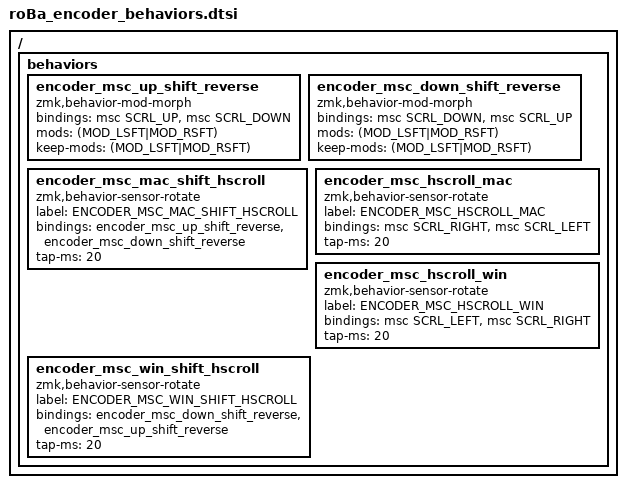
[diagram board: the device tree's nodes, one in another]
/ {
    behaviors {
        encoder_msc_up_shift_reverse: encoder_msc_up_shift_reverse {
            compatible = "zmk,behavior-mod-morph";
            #binding-cells = <0>;
            bindings = <&msc SCRL_UP>, <&msc SCRL_DOWN>;

            mods = <(MOD_LSFT|MOD_RSFT)>;
            keep-mods = <(MOD_LSFT|MOD_RSFT)>;
        };

        encoder_msc_down_shift_reverse: encoder_msc_down_shift_reverse {
            compatible = "zmk,behavior-mod-morph";
            #binding-cells = <0>;
            bindings = <&msc SCRL_DOWN>, <&msc SCRL_UP>;

            mods = <(MOD_LSFT|MOD_RSFT)>;
            keep-mods = <(MOD_LSFT|MOD_RSFT)>;
        };

        encoder_msc_mac_shift_hscroll: encoder_msc_mac_shift_hscroll {
            compatible = "zmk,behavior-sensor-rotate";
            label = "ENCODER_MSC_MAC_SHIFT_HSCROLL";
            #sensor-binding-cells = <0>;
            bindings = <&encoder_msc_up_shift_reverse>, <&encoder_msc_down_shift_reverse>;

            tap-ms = <20>;
        };

        // Window_Jesture系(ウィンドウ操作ジェスチャー層)でのエンコーダ横スクロール。
        // SCRL_LEFT/RIGHT(水平ホイールのネイティブHIDコード)を直接送る。Shiftには
        // 一切触れないため、旧実装(34e9cf9: LSHFTをmacroでpress/releaseする方式)で
        // 起きた「Shift解放漏れ→スクロール暴走」が構造的に発生しない。
        // 方向はMac/iPadのShift+ホイール変換時の体感(CW=右)に合わせる。

        encoder_msc_hscroll_mac: encoder_msc_hscroll_mac {
            compatible = "zmk,behavior-sensor-rotate";
            label = "ENCODER_MSC_HSCROLL_MAC";
            #sensor-binding-cells = <0>;
            bindings = <&msc SCRL_RIGHT>, <&msc SCRL_LEFT>;

            tap-ms = <20>;
        };

        // Windows版。縦スクロールがMac系と逆(encoder_msc_win_shift_hscroll参照)なのと
        // 同じ規則で、横も反転(CW=左)。実機で逆に感じたらbindingsを入れ替える。

        encoder_msc_hscroll_win: encoder_msc_hscroll_win {
            compatible = "zmk,behavior-sensor-rotate";
            label = "ENCODER_MSC_HSCROLL_WIN";
            #sensor-binding-cells = <0>;
            bindings = <&msc SCRL_LEFT>, <&msc SCRL_RIGHT>;

            tap-ms = <20>;
        };

        // Windows版のshift判定hscroll。回転方向はencoder_msc_up_downと同じ並び
        // （CW=DOWN/CCW=UP）にしつつ、既存のshift-reverse(mac用と共通)を再利用。
        // Shift+ホイール=横スクロールはWindowsだと純正機能ではなくアプリ依存。

        encoder_msc_win_shift_hscroll: encoder_msc_win_shift_hscroll {
            compatible = "zmk,behavior-sensor-rotate";
            label = "ENCODER_MSC_WIN_SHIFT_HSCROLL";
            #sensor-binding-cells = <0>;
            bindings = <&encoder_msc_down_shift_reverse>, <&encoder_msc_up_shift_reverse>;

            tap-ms = <20>;
        };
    };
};
